# D2522AA register map
Vendor: Dialog; Series: D2522AA; File version: 1.2
CPU: CM0 r1p0, little endian, MPU, FPU, 3 interrupt priority bits
Registers are 32-bit, read-write, reset 0x0 unless marked. A register's access mark holds for its fields unless they carry their own. Offsets are from the block's base; [hi:lo] are bit positions.

## SysTick — Cortex M0 SysTick registers
Base 0xE000E010
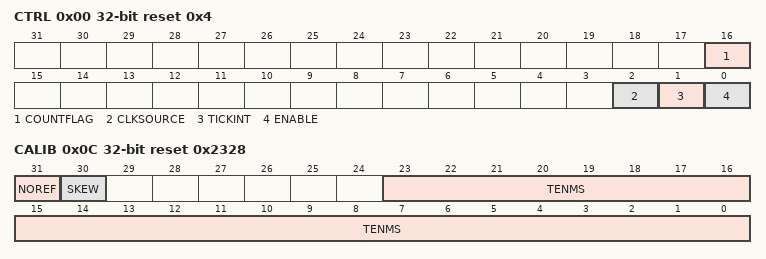
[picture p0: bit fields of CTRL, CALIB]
0x00 CTRL reset 0x4 — SysTick Control and Status register
  [16] COUNTFLAG — Timer counted to 0 since last time this was read
  [2] CLKSOURCE — Clock source selection
  [1] TICKINT — SysTick exception request enable
  [0] ENABLE — SysTick Counter enable
0x04 LOAD — SysTick Reload value register
  [23:0] RELOAD — RELOAD[23:0] bits (Reload value)
0x08 VAL — SysTick Current value register
  [23:0] CURRENT — CURRENT[23:0] bits (Current counter value)
0x0C CALIB ro reset 0x2328 — SysTick Calibration value register
  [31] NOREF — Indicates that a separate reference clock is provided
  [30] SKEW — Indicates whether the TENMS value is exact
  [23:0] TENMS — TENMS[23:0] bits (Calibration value)

## ANAMISC — ANAMISC registers
Base 0x50030B00
0x00 ANA_TEST_REG — Analog test registers
  [3:0] TEST_STRUCTURE — 4 bits to select which test-structure is mapped on P1[7] 0 : open 1 : VDD (1.2V) 2 : 10uA into 66k = 5/3 x 40k (W/L=0.45/22.33) 3 : 1uA into 700k = 18.5 x 40k (W/L=0.45/22.33) 4 : 1uA(same as going into 700k) 5 : AVS (0V) 6 : 5uA into nMOST (svt) 2x1u/110n 7 : 5uA into nMOST (hvt) 2x1u/110n 8 : 5uA into nMOST (UD18) 2x1u/260n 9 : 5uA into nMOST (OD33) 2x1u/500n a : 7.5uA into nMOST (na25) 4x1u/1.2u b : 5uA into nMOST (0vt) 4x1u/300n c : VDD - 5uA from pMOST (svt) 2x1u/110n d : VDD - 5uA from pMOST (hvt) 2x1u/110n e : VDD - 5uA from pMOST (OD33) 2x1u/400n f : VDD - 5uA from pMOST (UD18) 2x1u/260n
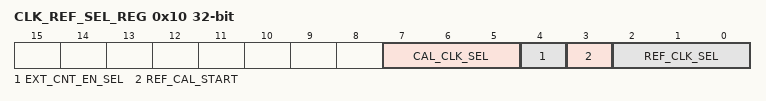
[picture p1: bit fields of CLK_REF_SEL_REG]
0x10 CLK_REF_SEL_REG — Select clock for oscillator calibration
  [7:5] CAL_CLK_SEL — Select reference clock input to be used in calibration: 0x0 : DIVN clock 0x1 : RC32K 0x2 : RC32M 0x3 : XTAL32K 0x4 : RCOSC 0x5, 0x6, 0x7: Reserved
  [4] EXT_CNT_EN_SEL — 0 : Enable XTAL_CNT counter by the REF_CLK selected by REF_CLK_SEL. 1 : Enable XTAL_CNT counter from an external input.
  [3] REF_CAL_START — Writing a '1' starts a calibration. This bit is cleared when calibration is finished, and CLK_REF_VAL is ready.
  [2:0] REF_CLK_SEL — Select clock input for calibration: 0x0 : RC32K 0x1 : RC32M 0x2 : XTAL32K 0x3 : RCX 0x4 : RCOSC
0x14 CLK_REF_CNT_REG — Count value for oscillator calibration
  [15:0] REF_CNT_VAL — Indicates the calibration time, with a decrement counter to 1.
0x18 CLK_REF_VAL_REG (reset mask 0x7FFFFFFF) — DIVN reference cycles, lower 16 bits
  [31:0] XTAL_CNT_VAL ro — Returns the number of DIVN clock cycles counted during the calibration time, defined with REF_CNT_VAL

## CHIP_VERSION — CHIP_VERSION registers
Base 0x50040200
0x00 CHIP_ID1_REG reset 0x32 — Chip identification register 1.
  [7:0] CHIP_ID1 ro — First character of device type "2522" in ASCII.
0x04 CHIP_ID2_REG reset 0x35 — Chip identification register 2.
  [7:0] CHIP_ID2 ro — Second character of device type "2522" in ASCII.
0x08 CHIP_ID3_REG reset 0x32 — Chip identification register 3.
  [7:0] CHIP_ID3 ro — Third character of device type "2522" in ASCII.
0x0C CHIP_ID4_REG reset 0x32 — Chip identification register 4.
  [7:0] CHIP_ID4 ro — Fourth character of device type "2522" in ASCII.
0x10 CHIP_SWC_REG — Software compatibility register.
  [3:0] CHIP_SWC ro — SoftWare Compatibility code. Integer (default = 0) which is incremented if a silicon change has impact on the CPU Firmware. Can be used by software developers to write silicon revision dependent code.
0x14 CHIP_REVISION_REG reset 0x41 — Chip revision register.
  [7:0] CHIP_REVISION ro — Chip version, corresponds with type number in ASCII. 0x41 = 'A', 0x42 = 'B'
0xF8 CHIP_TEST1_REG reset 0x41 — Chip test register 1.
  [7:0] CHIP_LAYOUT_REVISION ro — Chip layout revision, corresponds with type number in ASCII. 0x41 = 'A', 0x42 = 'B'
0xFC CHIP_TEST2_REG — Chip test register 2.
  [3:0] CHIP_METAL_OPTION ro — Chip metal option value.
